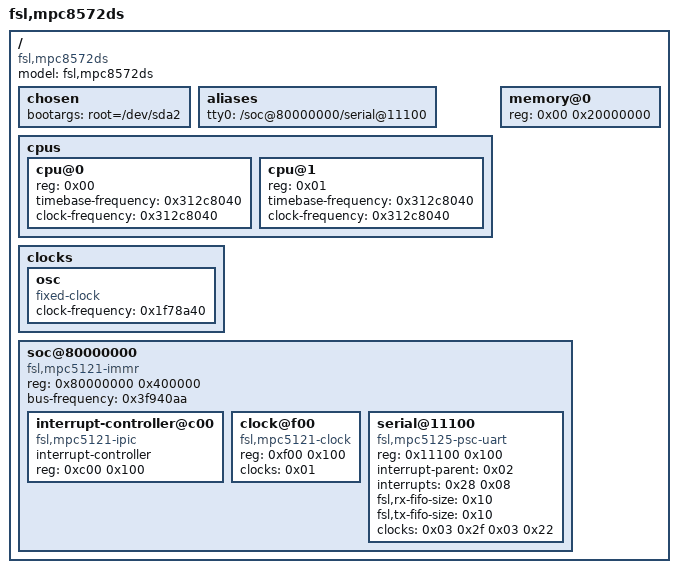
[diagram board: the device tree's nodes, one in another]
/dts-v1/;

/ {
	model = "fsl,mpc8572ds";
	compatible = "fsl,mpc8572ds";
	#address-cells = <0x01>;
	#size-cells = <0x01>;

	chosen {
		bootargs = "root=/dev/sda2";
	};

	aliases {
		tty0 = "/soc@80000000/serial@11100";
	};

	cpus {
		#address-cells = <0x01>;
		#size-cells = <0x00>;

		cpu@0 {
			device_type = "cpu";
			reg = <0x00>;
			timebase-frequency = <0x312c8040>;
			clock-frequency = <0x312c8040>;
		};

		cpu@1 {
			device_type = "cpu";
			reg = <0x01>;
			timebase-frequency = <0x312c8040>;
			clock-frequency = <0x312c8040>;
		};
	};

	memory@0 {
		device_type = "memory";
		reg = <0x00 0x20000000>;
	};

	clocks {
		#address-cells = <0x01>;
		#size-cells = <0x00>;

		osc {
			compatible = "fixed-clock";
			#clock-cells = <0x00>;
			clock-frequency = <0x1f78a40>;
			phandle = <0x01>;
		};
	};

	soc@80000000 {
		compatible = "fsl,mpc5121-immr";
		#address-cells = <0x01>;
		#size-cells = <0x01>;
		device_type = "soc";
		ranges = <0x00 0x80000000 0x400000>;
		reg = <0x80000000 0x400000>;
		bus-frequency = <0x3f940aa>;

		interrupt-controller@c00 {
			compatible = "fsl,mpc5121-ipic\0fsl,ipic";
			interrupt-controller;
			#address-cells = <0x00>;
			#interrupt-cells = <0x02>;
			reg = <0xc00 0x100>;
			phandle = <0x02>;
		};

		clock@f00 {
			compatible = "fsl,mpc5121-clock";
			reg = <0xf00 0x100>;
			#clock-cells = <0x01>;
			clocks = <0x01>;
			clock-names = "osc";
			phandle = <0x03>;
		};

		serial@11100 {
			compatible = "fsl,mpc5125-psc-uart\0fsl,mpc5125-psc";
			reg = <0x11100 0x100>;
			interrupt-parent = <0x02>;
			interrupts = <0x28 0x08>;
			fsl,rx-fifo-size = <0x10>;
			fsl,tx-fifo-size = <0x10>;
			clocks = <0x03 0x2f 0x03 0x22>;
			clock-names = "ipg\0mclk";
		};
	};
};
